# psoc6_01 register map
Vendor: Infineon Technologies; Series: PSOC6_01; File version: 1.0
CPU: CM4 r0p1, little endian, MPU, FPU, VTOR, 3 interrupt priority bits
Registers are 32-bit, read-write, reset 0x0 unless marked. A register's access mark holds for its fields unless they carry their own. Offsets are from the block's base; [hi:lo] are bit positions; lines under a group give offsets from that group; {n}, {i} and the like mark numbered series; 'fields as' and 'values as' point back to an identical list.

## PERI — Peripheral interconnect
Base 0x40010000
{0x0+0x40*i} GR[{i}] (i=0..10) group — Peripheral group structure
  0x00 CLOCK_CTL — Clock control
    [15:8] INT8_DIV — Specifies a group clock divider (from the peripheral clock 'clk_peri' to the group clock 'clk_group[3/4/5/...15]'). Integer division by (1+INT8_DIV). Allows for integer divisions in the range [1, 256]. Note that this field is retained. However, the counter that is used to implement the division is not and will be initialized by HW to '0' when transitioning from DeepSleep to Active power mode.
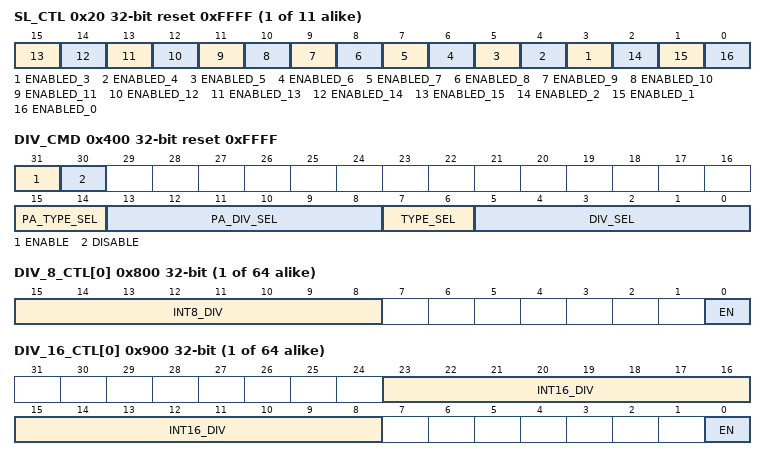
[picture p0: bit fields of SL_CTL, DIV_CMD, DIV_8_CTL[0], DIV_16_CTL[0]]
  0x20 SL_CTL reset 0xFFFF — Slave control
    [n] ENABLED_{n} (n=3..15)
    [2] ENABLED_2 — Peripheral group, slave 2 enable. If the slave is disabled, its clock is gated off (constant '0') and its resets are activated. Note: For peripheral group 0 (the peripheral interconnect, master interface MMIO registers), this field is a constant '1' (SW: R): the slave can NOT be disabled.
    [1] ENABLED_1 — Peripheral group, slave 1 enable. If the slave is disabled, its clock is gated off (constant '0') and its resets are activated. Note: For peripheral group 0 (the peripheral interconnect MMIO registers), this field is a constant '1' (SW: R): the slave can NOT be disabled.
    [0] ENABLED_0 ro — Peripheral group, slave 0 enable. This field is for the peripheral group internal MMIO register slave (PPU structures) and is a constant '1'. This slave can NOT be disabled.
  0x24 TIMEOUT_CTL reset 0xFFFF — Timeout control
    [15:0] TIMEOUT — This field specifies a number of peripheral group (clk_group) clock cycles. If an AHB-Lite bus transfer takes more than the specified number of cycles (timeout detection), the bus transfer is terminated with an AHB-Lite bus error and a fault is generated (and possibly recorded in the fault report structure(s)). '0x0000'-'0xfffe': Number of peripheral group clock cycles. '0xffff': This value is the default/reset value and specifies that no timeout detection is performed: a bus transfer will never be terminated and a fault will never be generated.
0x400 DIV_CMD reset 0xFFFF — Divider command register
  [31] ENABLE — Clock divider enable command (mutually exclusive with DISABLE). Typically, SW sets this field to '1' to enable a divider and HW sets this field to '0' to indicate that divider enabling has completed. When a divider is enabled, its integer and fractional (if present) counters are initialized to '0'. If a divider is to be re-enabled using different integer and fractional divider values, the SW should follow these steps: 0: Disable the divider using the DIV_CMD.DISABLE field. 1: Configure the divider's DIV_XXX_CTL register. 2: Enable the divider using the DIV_CMD_ENABLE field. The DIV_SEL and TYPE_SEL fields specify which divider is to be enabled. The enabled divider may be phase aligned to either 'clk_peri' (typical usage) or to ANY enabled divider. The PA_DIV_SEL and PA_TYPE_SEL fields specify the reference divider. The HW sets the ENABLE field to '0' when the enabling is performed and the HW set the DIV_XXX_CTL.EN field of the divider to '1' when the enabling is performed. Note that enabling with phase alignment to a low frequency divider takes time. E.g. To align to a divider that generates a clock of 'clk_peri'/n (with n being the integer divider value INT_DIV+1), up to n cycles may be required to perform alignment. Phase alignment to 'clk_peri' takes affect immediately. SW can set this field to '0' during phase alignment to abort the enabling process.
  [30] DISABLE — Clock divider disable command (mutually exclusive with ENABLE). SW sets this field to '1' and HW sets this field to '0'. The DIV_SEL and TYPE_SEL fields specify which divider is to be disabled. The HW sets the DISABLE field to '0' immediately and the HW sets the DIV_XXX_CTL.EN field of the divider to '0' immediately.
  [15:14] PA_TYPE_SEL — Specifies the divider type of the divider to which phase alignment is performed for the clock enable command: 0: 8.0 (integer) clock dividers. 1: 16.0 (integer) clock dividers. 2: 16.5 (fractional) clock dividers. 3: 24.5 (fractional) clock dividers.
  [13:8] PA_DIV_SEL — (PA_TYPE_SEL, PA_DIV_SEL) specifies the divider to which phase alignment is performed for the clock enable command. Any enabled divider can be used as reference. This allows all dividers to be aligned with each other, even when they are enabled at different times. If PA_DIV_SEL is '63' and PA_TYPE_SEL is '3', 'clk_peri' is used as reference.
  [7:6] TYPE_SEL — Specifies the divider type of the divider on which the command is performed: 0: 8.0 (integer) clock dividers. 1: 16.0 (integer) clock dividers. 2: 16.5 (fractional) clock dividers. 3: 24.5 (fractional) clock dividers.
  [5:0] DIV_SEL — (TYPE_SEL, DIV_SEL) specifies the divider on which the command (DISABLE/ENABLE) is performed. If DIV_SEL is '63' and TYPE_SEL is '3' (default/reset value), no divider is specified and no clock signal(s) are generated.
{0x800+4i} DIV_8_CTL[{i}] (i=0..63) — Divider control register (for 8.0 divider)
  [15:8] INT8_DIV — Integer division by (1+INT8_DIV). Allows for integer divisions in the range [1, 256]. Note: this type of divider does NOT allow for a fractional division. For the generation of a divided clock, the integer division range is restricted to [2, 256]. For the generation of a 50/50 percent duty cycle digital divided clock, the integer division range is resticited to even numbers in the range [2, 256]. The generation of a 50/50 percent duty cycle analog divided clock has no restrictions. Note that this field is retained. However, the counter that is used to implement the division is not and will be initialized by HW to '0' when transitioning from DeepSleep to Active power mode.
  [0] EN ro — Divider enabled. HW sets this field to '1' as a result of an ENABLE command. HW sets this field to '0' as a result on a DISABLE command. Note that this field is retained. As a result, the divider does NOT have to be re-enabled after transitioning from DeepSleep to Active power mode.
{0x900+4i} DIV_16_CTL[{i}] (i=0..63) — Divider control register (for 16.0 divider)
  [23:8] INT16_DIV — Integer division by (1+INT16_DIV). Allows for integer divisions in the range [1, 65,536]. Note: this type of divider does NOT allow for a fractional division. For the generation of a divided clock, the integer division range is restricted to [2, 65,536]. For the generation of a 50/50 percent duty cycle digital divided clock, the integer division range is restricted to even numbers in the range [2, 65,536]. The generation of a 50/50 percent duty cycle analog divided clock has no restrictions. Note that this field is retained. However, the counter that is used to implement the division is not and will be initialized by HW to '0' when transitioning from DeepSleep to Active power mode.
  [0] EN ro — Divider enabled. HW sets this field to '1' as a result of an ENABLE command. HW sets this field to '0' as a result on a DISABLE command. Note that this field is retained. As a result, the divider does NOT have to be re-enabled after transitioning from DeepSleep to Active power mode.
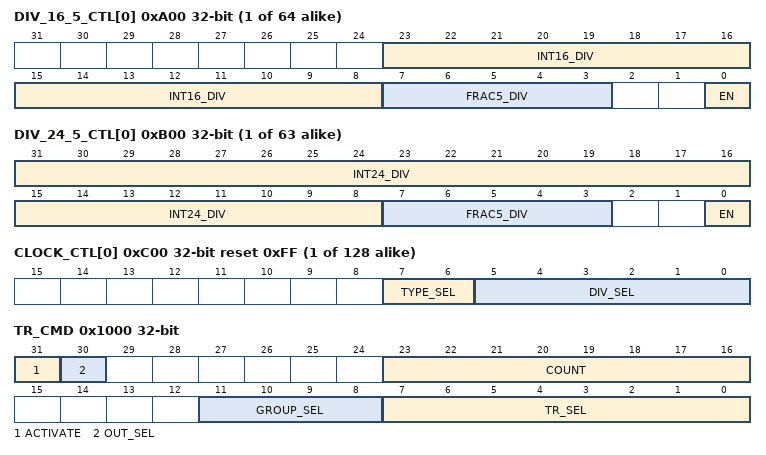
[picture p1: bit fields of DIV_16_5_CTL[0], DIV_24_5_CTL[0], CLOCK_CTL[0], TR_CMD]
{0xA00+4i} DIV_16_5_CTL[{i}] (i=0..63) — Divider control register (for 16.5 divider)
  [23:8] INT16_DIV — Integer division by (1+INT16_DIV). Allows for integer divisions in the range [1, 65,536]. Note: combined with fractional division, this divider type allows for a division in the range [1, 65,536 31/32] in 1/32 increments. For the generation of a divided clock, the division range is restricted to [2, 65,536 31/32]. For the generation of a 50/50 percent duty cycle divided clock, the division range is restricted to [2, 65,536]. Note that this field is retained. However, the counter that is used to implement the division is not and will be initialized by HW to '0' when transitioning from DeepSleep to Active power mode.
  [7:3] FRAC5_DIV — Fractional division by (FRAC5_DIV/32). Allows for fractional divisions in the range [0, 31/32]. Note that fractional division results in clock jitter as some clock periods may be 1 'clk_peri' cycle longer than other clock periods. Note that this field is retained. However, the counter that is used to implement the division is not and will be initialized by HW to '0' when transitioning from DeepSleep to Active power mode.
  [0] EN ro — Divider enabled. HW sets this field to '1' as a result of an ENABLE command. HW sets this field to '0' as a result on a DISABLE command. Note that this field is retained. As a result, the divider does NOT have to be re-enabled after transitioning from DeepSleep to Active power mode.
{0xB00+4i} DIV_24_5_CTL[{i}] (i=0..62) — Divider control register (for 24.5 divider)
  [31:8] INT24_DIV — Integer division by (1+INT24_DIV). Allows for integer divisions in the range [1, 16,777,216]. Note: combined with fractional division, this divider type allows for a division in the range [1, 16,777,216 31/32] in 1/32 increments. For the generation of a divided clock, the integer division range is restricted to [2, 16,777,216 31/32]. For the generation of a 50/50 percent duty cycle divided clock, the division range is restricted to [2, 16,777,216]. Note that this field is retained. However, the counter that is used to implement the division is not and will be initialized by HW to '0' when transitioning from DeepSleep to Active power mode.
  [7:3] FRAC5_DIV — Fractional division by (FRAC5_DIV/32). Allows for fractional divisions in the range [0, 31/32]. Note that fractional division results in clock jitter as some clock periods may be 1 'clk_peri' cycle longer than other clock periods. Note that this field is retained. However, the counter that is used to implement the division is not and will be initialized by HW to '0' when transitioning from DeepSleep to Active power mode.
  [0] EN ro — Divider enabled. HW sets this field to '1' as a result of an ENABLE command. HW sets this field to '0' as a result on a DISABLE command. Note that this field is retained. As a result, the divider does NOT have to be re-enabled after transitioning from DeepSleep to Active power mode.
{0xC00+4i} CLOCK_CTL[{i}] (i=0..127) reset 0xFF — Clock control register
  [7:6] TYPE_SEL — Specifies divider type: 0: 8.0 (integer) clock dividers. 1: 16.0 (integer) clock dividers. 2: 16.5 (fractional) clock dividers. 3: 24.5 (fractional) clock dividers.
  [5:0] DIV_SEL — Specifies one of the dividers of the divider type specified by TYPE_SEL. If DIV_SEL is '63' and TYPE_SEL is '3' (default/reset value), no divider is specified and no clock control signal(s) are generated. When transitioning a clock between two out-of-phase dividers, spurious clock control signals may be generated for one 'clk_peri' cycle during this transition. These clock control signals may cause a single clock period that is smaller than any of the two divider periods. To prevent these spurious clock signals, the clock multiplexer can be disconnected (DIV_SEL is '63' and TYPE_SEL is '3') for a transition time that is larger than the smaller of the two divider periods.
0x1000 TR_CMD — Trigger command register
  [31] ACTIVATE — SW sets this field to '1' by to activate (set to '1') a trigger as identified by TR_SEL and OUT_SEL for COUNT cycles. HW sets this field to '0' when the cycle counter is decremented to '0'. Note: a COUNT value of 255 is a special case and trigger activation is under direct control of the ACTIVATE field (the counter is not decremented).
  [30] OUT_SEL — Specifies whether trigger activation is for a specific input or ouput trigger of the trigger multiplexer. Activation of a specific input trigger, will result in activation of all output triggers that have the specific input trigger selected through their TR_OUT_CTL.TR_SEL field. Activation of a specific output trigger, will result in activation of the specified TR_SEL output trigger only. '0': TR_SEL selection and trigger activation is for an input trigger to the trigger multiplexer. '1': TR_SEL selection and trigger activation is for an output trigger from the trigger multiplexer.
  [23:16] COUNT — Amount of 'clk_peri' cycles a specific trigger is activated. During activation (ACTIVATE is '1'), HW decrements this field to '0' using a cycle counter. During activation, SW should not modify this register field. A value of 255 is a special case: HW does NOT decrement this field to '0' and trigger activation is under direct control of ACTIVATE when ACTIVATE is '1' the trigger is activated and when ACTIVATE is '0' the trigger is deactivated.
  [11:8] GROUP_SEL — Specifies the trigger group.
  [7:0] TR_SEL — Specifies the activated trigger when ACTIVATE is '1'. OUT_SEL specifies whether the activated trigger is an input trigger or output trigger to the trigger multiplexer. During activation (ACTIVATE is '1'), SW should not modify this register field. If the specified trigger is not present, the trigger activation has no effect.
{0x2000+0x200*i} TR_GR[{i}] (i=0..14) group — Trigger group
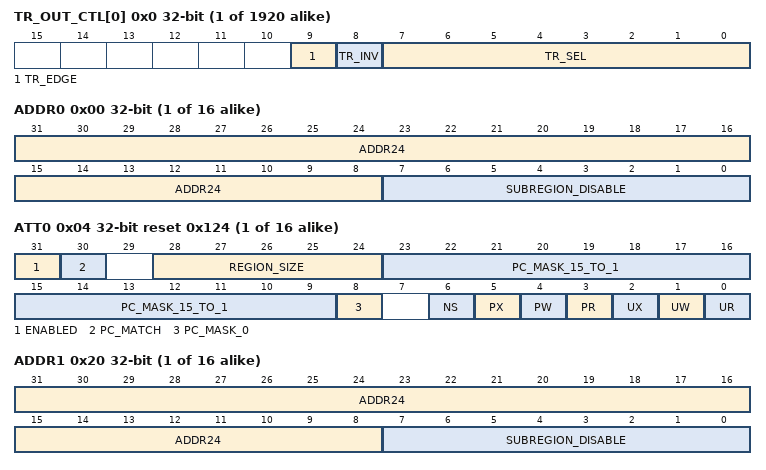
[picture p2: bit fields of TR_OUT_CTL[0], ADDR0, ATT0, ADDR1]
  {0x0+4j} TR_OUT_CTL[{j}] (j=0..127) — Trigger control register
    [9] TR_EDGE — Specifies if the (inverted) output trigger is treated as a level sensitive or edge sensitive trigger. '0': level sensitive. '1': edge sensitive trigger. The (inverted) output trigger duration needs to be at least 2 cycles on the consumer clock. the(inverted) output trigger is synchronized to the consumer clock and a two cycle pulse is generated on the consumer clock.
    [8] TR_INV — Specifies if the output trigger is inverted.
    [7:0] TR_SEL — Specifies input trigger. This field is typically set during the setup of a chip use case scenario. Changing this field while activated triggers are present on the input triggers may result in unpredictable behavior. Note that input trigger 0 (default value) is typically connected to a constant signal level of '0', and as a result will not cause HW activation of the output trigger.
{0x4000+0x40*i} PPU_PR[{i}] (i=0..15) group — PPU structure with programmable address
  0x00 ADDR0 reset not defined — PPU region address 0 (slave structure)
    [31:8] ADDR24 — This field specifies the most significant bits of the 32-bit address of an address region. The region size is defined by PPU_REGION_ATT.REGION_SIZE. A region of n Byte is always n Byte aligned. As a result, some of the lesser significant address bits of ADDR24 may be ignored in determining whether a bus transfer address is within an address region. E.g., a 64 KByte address region (REGION_SIZE is '15') is 64 KByte aligned, and ADDR24[7:0] are ignored.
    [7:0] SUBREGION_DISABLE — This field is used to individually disabled the eight equally sized subregions in which a region is partitioned. Subregion disable: Bit 0: subregion 0 disable. Bit 1: subregion 1 disable. Bit 2: subregion 2 disable. Bit 3: subregion 3 disable. Bit 4: subregion 4 disable. Bit 5: subregion 5 disable. Bit 6: subregion 6 disable. Bit 7: subregion 7 disable. E.g., a 64 KByte address region (REGION_SIZE is '15') has eight 8 KByte subregions. The access control as defined by PPU_REGION_ATT applies if the bus transfer address is within the address region AND the addressed subregion is NOT disabled. Note that the smallest region size is 256 B and the smallest subregion size is 32 B.
  0x04 ATT0 reset 0x124 (reset mask 0x80000124) — PPU region attributes 0 (slave structure)
    [31] ENABLED — Region enable: '0': Disabled. A disabled region will never result in a match on the bus transfer address. '1': Enabled. Note: a disabled address region performs logic gating to reduce dynamic power consumption.
    [30] PC_MATCH — This field specifies if the PC field participates in the 'matching' process or the 'access evaluation' process: '0': PC field participates in 'access evaluation'. '1': PC field participates in 'matching'. Note that it is possible to define different access control for multiple protection contexts by using multiple protection structures with the same address region and PC_MATCH set to '1'.
    [28:24] REGION_SIZE — This field specifies the region size: '0'-'6': Undefined. '7': 256 B region '8': 512 B region '9': 1 KB region '10': 2 KB region '11': 4 KB region '12': 8 KB region '13': 16 KB region '14': 32 KB region '15': 64 KB region '16': 128 KB region '17': 256 KB region '18': 512 KB region '19': 1 MB region '20': 2 MB region '21': 4 MB region '22': 8 MB region '23': 16 MB region '24': 32 MB region '25': 64 MB region '26': 128 MB region '27': 256 MB region '28': 512 MB region '29': 1 GB region '30': 2 GB region '31': 4 GB region
    [23:9] PC_MASK_15_TO_1 — This field specifies protection context identifier based access control. Bit i: protection context i+1 enable. If '0', protection context i+1 access is disabled; i.e. not allowed. If '1', protection context i+1 access is enabled; i.e. allowed.
    [8] PC_MASK_0 ro — This field specifies protection context identifier based access control for protection context '0'.
    [6] NS — Non-secure: '0': Secure (secure accesses allowed, non-secure access NOT allowed). '1': Non-secure (both secure and non-secure accesses allowed).
    [5] PX ro — Privileged execute enable: '0': Disabled (privileged, execute accesses are NOT allowed). '1': Enabled (privileged, execute accesses are allowed).
    [4] PW — Privileged write enable: '0': Disabled (privileged, write accesses are NOT allowed). '1': Enabled (privileged, write accesses are allowed).
    [3] PR — Privileged read enable: '0': Disabled (privileged, read accesses are NOT allowed). '1': Enabled (privileged, read accesses are allowed).
    [2] UX ro — User execute enable: '0': Disabled (user, execute accesses are NOT allowed). '1': Enabled (user, execute accesses are allowed).
    [1] UW — User write enable: '0': Disabled (user, write accesses are NOT allowed). '1': Enabled (user, write accesses are allowed).
    [0] UR — User read enable: '0': Disabled (user, read accesses are NOT allowed). '1': Enabled (user, read accesses are allowed).
  0x20 ADDR1 ro — PPU region address 1 (master structure)
    [31:8] ADDR24 — See corresponding field for PPU structure with programmable address. 'ADDR_DEF1': base address of structure. Note: this field is read-only.
    [7:0] SUBREGION_DISABLE — See corresponding field for PPU structure with programmable address. Two out of a total of eight 32 B subregions are enabled. These subregions includes region structures 0 and 1. Note: this field is read-only.
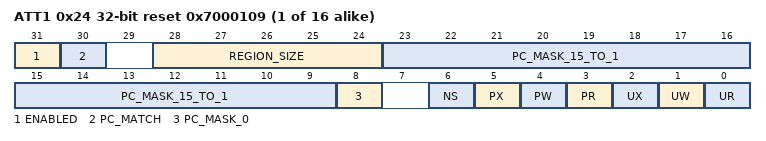
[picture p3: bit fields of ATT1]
  0x24 ATT1 reset 0x7000109 (reset mask 0x9F00012D) — PPU region attributes 1 (master structure)
    [31] ENABLED — See corresponding field for PPU structure with programmable address.
    [30] PC_MATCH — See corresponding field for PPU structure with programmable address.
    [28:24] REGION_SIZE ro — See corresponding field for PPU structure with programmable address. '7': 256 B region
    [23:9] PC_MASK_15_TO_1 — See corresponding field for PPU structure with programmable address.
    [8] PC_MASK_0 ro — See corresponding field for PPU structure with programmable address.
    [6] NS — See corresponding field for PPU structure with programmable address.
    [5] PX ro — See corresponding field for PPU structure with programmable address. Note that this register is constant '0'; i.e. privileged execute accesses are NEVER allowed.
    [4] PW — See corresponding field for PPU structure with programmable address.
    [3] PR ro — See corresponding field for PPU structure with programmable address. Note that this register is constant '1'; i.e. privileged read accesses are ALWAYS allowed.
    [2] UX ro — See corresponding field for PPU structure with programmable address. Note that this register is constant '0'; i.e. user execute accesses are NEVER allowed.
    [1] UW — See corresponding field for PPU structure with programmable address.
    [0] UR ro — See corresponding field for PPU structure with programmable address. Note that this register is constant '1'; i.e. user read accesses are ALWAYS allowed.
{0x5000+0x40*i} PPU_GR[{i}] (i=0..10) group — PPU structure with fixed/constant address for a peripheral group
  0x00 ADDR0 ro — PPU region address 0 (slave structure)
    [31:8] ADDR24 — See corresponding field for PPU structure with programmable address. 'ADDR_DEF1': address of protected region. Note: this field is read-only. Its value is chip specific.
    [7:0] SUBREGION_DISABLE — See corresponding field for PPU structure with programmable address. Note: this field is read-only. Its value is chip specific.
  0x04 ATT0 reset 0x124 (reset mask 0x9F000124) — PPU region attributes 0 (slave structure)
    [31] ENABLED — See corresponding field for PPU structure with programmable address.
    [30] PC_MATCH — See corresponding field for PPU structure with programmable address.
    [28:24] REGION_SIZE ro — See corresponding field for PPU structure with programmable address. Note: this field is read-only. Its value is chip specific.
    [23:9] PC_MASK_15_TO_1 — See corresponding field for PPU structure with programmable address.
    [8] PC_MASK_0 ro — See corresponding field for PPU structure with programmable address.
    [6] NS — See corresponding field for PPU structure with programmable address.
    [5] PX ro — See corresponding field for PPU structure with programmable address. Note that this register is constant '1'; i.e. user execute accesses are ALWAYS allowed.
    [4] PW — See corresponding field for PPU structure with programmable address.
    [3] PR — See corresponding field for PPU structure with programmable address.
    [2] UX ro — See corresponding field for PPU structure with programmable address. Note that this register is constant '1'; i.e. user execute accesses are ALWAYS allowed.
    [1] UW — See corresponding field for PPU structure with programmable address.
    [0] UR — See corresponding field for PPU structure with programmable address.
  0x20 ADDR1 ro — PPU region address 1 (master structure)
    fields as PPU_PR[0].ADDR1
  0x24 ATT1 reset 0x7000109 (reset mask 0x9F00012D) — PPU region attributes 1 (master structure)
    fields as PPU_PR[0].ATT1

## Notices in the file
(c) (2016-2026), Infineon Technologies AG
or an affiliate of Infineon Technologies AG.
SPDX-License-Identifier: Apache-2.0
Licensed under the Apache License, Version 2.0 (the "License");
you may not use this file except in compliance with the License.
You may obtain a copy of the License at
http://www.apache.org/licenses/LICENSE-2.0
Unless required by applicable law or agreed to in writing, software
distributed under the License is distributed on an "AS IS" BASIS,
WITHOUT WARRANTIES OR CONDITIONS OF ANY KIND, either express or implied.
See the License for the specific language governing permissions and
limitations under the License.
